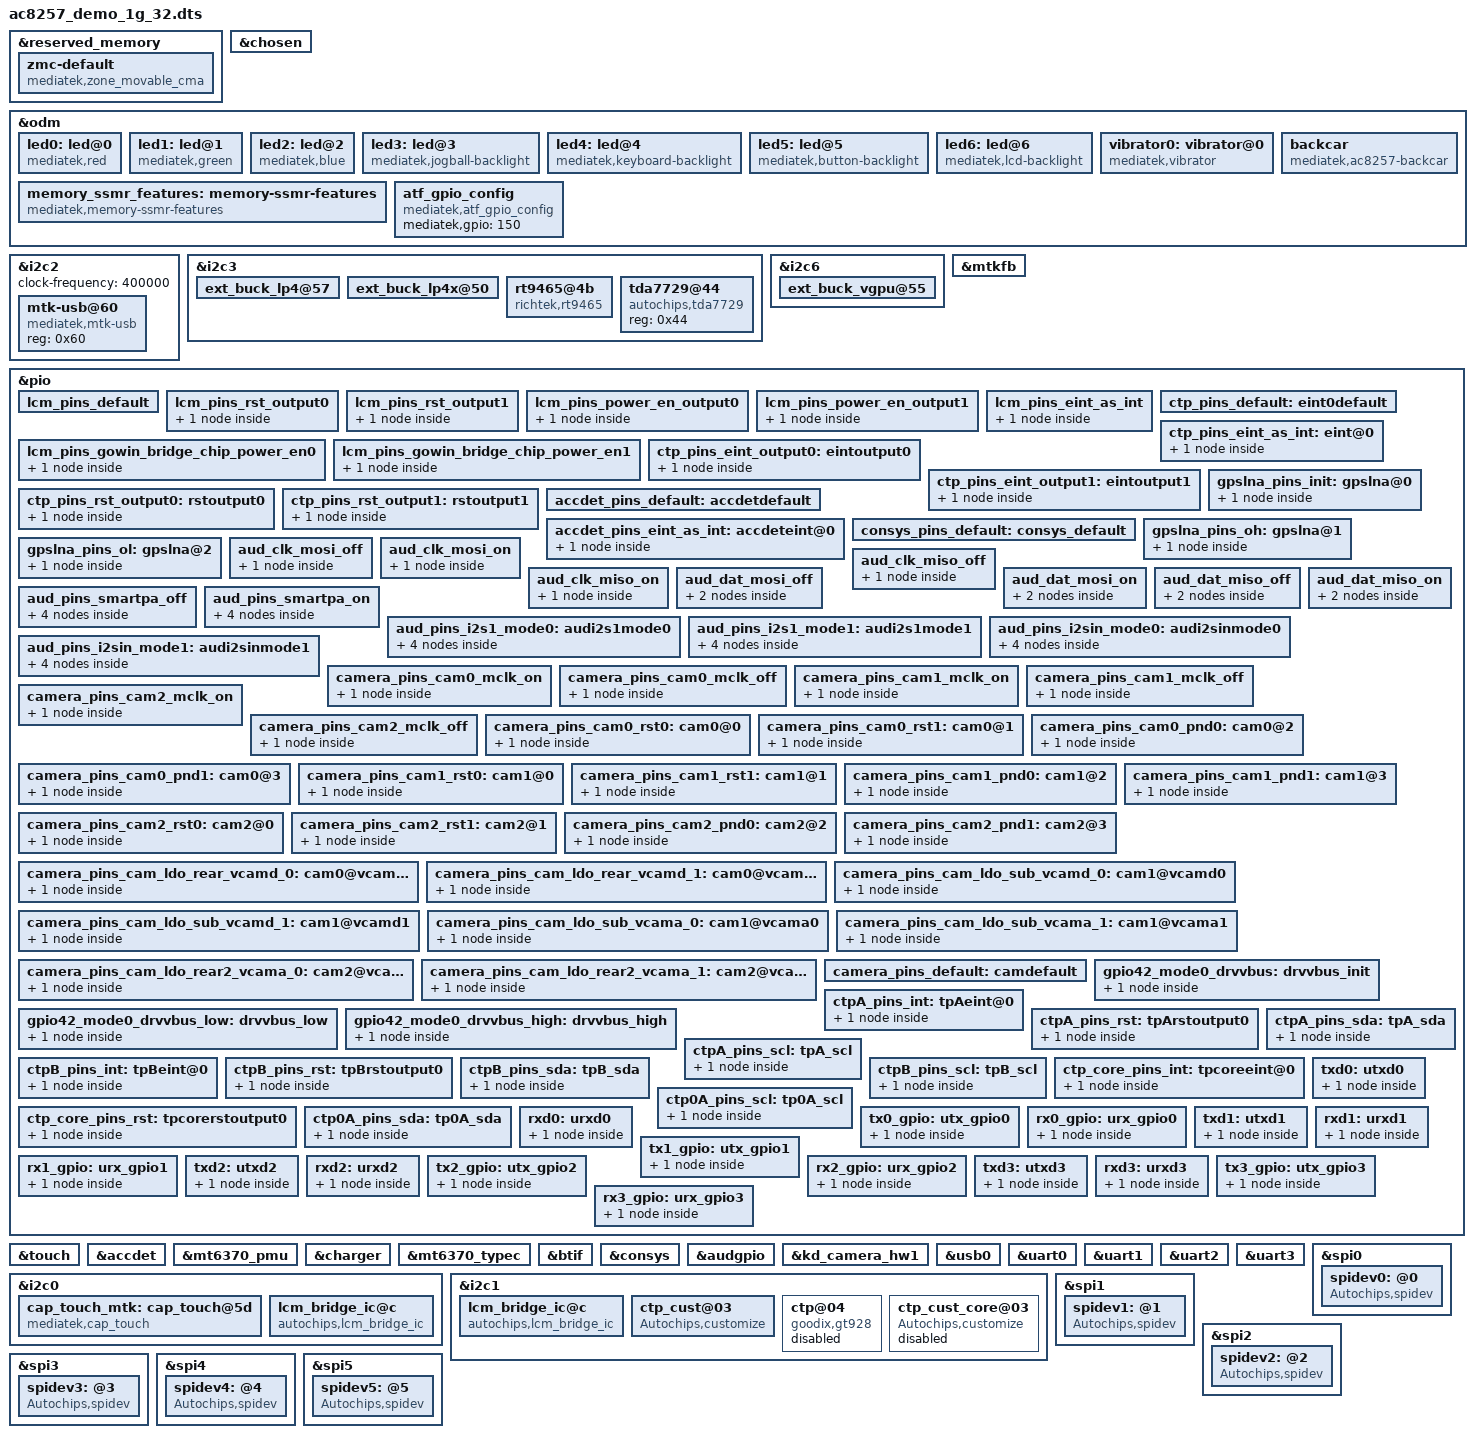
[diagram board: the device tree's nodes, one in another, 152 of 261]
#include <dt-bindings/interrupt-controller/arm-gic.h>
#include <dt-bindings/interrupt-controller/irq.h>
#include <dt-bindings/pinctrl/ac8257-pinfunc.h>
#include <dt-bindings/mmc/ac8257-msdc.h>
#include <dt-bindings/clock/ac8257-clk.h>

/dts-v1/;
/plugin/;

&reserved_memory {
	#address-cells = <2>;
	#size-cells = <2>;
	ranges;

	zmc-default {
		compatible = "mediatek,zone_movable_cma";
		size = <0 0xffc00000>;
		alignment = <0 0x10000000>;
		alloc-ranges = <0 0xc0000000 1 0x00000000>;
	};
};

/* chosen */
&chosen {

	/* fpga may has no lk, we need to specify display info here */
	/* fb buffer is reserved using this dts by memory node above */
	atag,videolfb-fb_base_h = <0x0>;
	atag,videolfb-fb_base_l = <0x5e605000>;
	atag,videolfb-islcmfound = <1>;
	/* because no lk, so lcm is not inited */
	atag,videolfb-islcm_inited = <0>;
	atag,videolfb-fps= <6000>;
	atag,videolfb-vramSize= <0x017bb000>;
	atag,videolfb-lcmname= "nt35521_hd_dsi_vdo_truly_rt5081_drv";
};

&odm {
	led0:led@0 {
		compatible = "mediatek,red";
		led_mode = <0>;
		data = <1>;
		pwm_config = <0 0 0 0 0>;
	};
	led1:led@1 {
		compatible = "mediatek,green";
		led_mode = <0>;
		data = <1>;
		pwm_config = <0 0 0 0 0>;
	};
	led2:led@2 {
		compatible = "mediatek,blue";
		led_mode = <0>;
		data = <1>;
		pwm_config = <0 0 0 0 0>;
	};
	led3:led@3 {
		compatible = "mediatek,jogball-backlight";
		led_mode = <0>;
		data = <1>;
		pwm_config = <0 0 0 0 0>;
	};
	led4:led@4 {
		compatible = "mediatek,keyboard-backlight";
		led_mode = <0>;
		data = <1>;
		pwm_config = <0 0 0 0 0>;
	};
	led5:led@5 {
		compatible = "mediatek,button-backlight";
		led_mode = <0>;
		data = <1>;
		pwm_config = <0 0 0 0 0>;
	};
	led6:led@6 {
		compatible = "mediatek,lcd-backlight";
		led_mode = <5>;
		data = <1>;
		pwm_config = <0 0 0 0 0>;
	};
	vibrator0:vibrator@0 {
		compatible = "mediatek,vibrator";
		vib_timer = <25>;
		vib_limit = <9>;
		vib_vol= <9>;
	};
	memory_ssmr_features: memory-ssmr-features {
		compatible = "mediatek,memory-ssmr-features";
		svp-size = <0 0>;
		iris-recognition-size = <0 0>;
		2d_fr-size = <0 0>;
		tui-size = <0 0>;
		wfd-size = <0 0>;
		prot-sharedmem-size = <0 0>;
	};
	backcar:backcar {
		compatible = "mediatek,ac8257-backcar";
		backcar_sdbc_gpio=<&pio 10 0>;
		backcar_hdbc_gpio=<&pio 6 0>;
		backcar_hdavm_gpio=<&pio 7 0>;
		backcar_mcu_notify_gpio=<&pio 55 0>;
		status="okay";
	};
	atf_gpio_config: atf_gpio_config {
		compatible = "mediatek,atf_gpio_config";
		mediatek,gpio = <150>;
	};
};

&i2c2 {
	#address-cells = <1>;
	#size-cells = <0>;
	clock-frequency = <400000>;

	mtk-usb@60 {
		compatible = "mediatek,mtk-usb";
		reg = <0x60>;
		status = "okay";
	};
};

&i2c3 {
	ext_buck_lp4@57 {
		regulator-name ="ext_buck_vdd2";
		regulator-min-microvolt = <300000>;
		regulator-max-microvolt = <1300000>;
		vsel_pin = <0>;
	};

	ext_buck_lp4x@50 {
		regulator-name ="ext_buck_vddq";
		regulator-min-microvolt = <300000>;
		regulator-max-microvolt = <1300000>;
		vsel_pin = <1>;
	};
};

&i2c6 {
	ext_buck_vgpu@55 {
		regulator-name ="ext_buck_vgpu";
		regulator-min-microvolt = <300000>;
		regulator-max-microvolt = <1300000>;
		vsel_pin = <2>;
	};
};

/*LCM start*/
&mtkfb {
	pinctrl-names = "default", "state_rst_output0", "state_rst_output1", "state_power_en_output0", "state_power_en_output1", "state_eint_as_int", "state_gowin_bridge_chip_power_en0", "state_gowin_bridge_chip_power_en1";
	pinctrl-0 = <&lcm_pins_default>;
	pinctrl-1 = <&lcm_pins_rst_output0>;
	pinctrl-2 = <&lcm_pins_rst_output1>;
	pinctrl-3 = <&lcm_pins_power_en_output0>;
	pinctrl-4 = <&lcm_pins_power_en_output1>;
	pinctrl-5 = <&lcm_pins_eint_as_int>;
	pinctrl-6 = <&lcm_pins_gowin_bridge_chip_power_en0>;
	pinctrl-7 = <&lcm_pins_gowin_bridge_chip_power_en1>;
	interrupt-parent = <&pio>;
	interrupts = <3 IRQ_TYPE_LEVEL_HIGH 3 0>;
	status = "okay";
};
&pio {
	lcm_pins_default: lcm_pins_default {
	};
	lcm_pins_rst_output0: lcm_pins_rst_output0 {
		pins_cmd_dat {
			pinmux = <PINMUX_GPIO45__FUNC_GPIO45>;
			slew-rate = <1>;
			output-low;
		};
	};
	lcm_pins_rst_output1: lcm_pins_rst_output1 {
		pins_cmd_dat {
			pinmux = <PINMUX_GPIO45__FUNC_GPIO45>;
			slew-rate = <1>;
			output-high;
		};
	};
	lcm_pins_power_en_output0: lcm_pins_power_en_output0 {
		pins_cmd_dat {
			pinmux = <PINMUX_GPIO159__FUNC_GPIO159>;
			slew-rate = <1>;
			output-low;
		};
	};
	lcm_pins_power_en_output1: lcm_pins_power_en_output1 {
		pins_cmd_dat {
			pinmux = <PINMUX_GPIO159__FUNC_GPIO159>;
			slew-rate = <1>;
			output-high;
		};
	};
	lcm_pins_eint_as_int: lcm_pins_eint_as_int {
		pins_cmd_dat {
			pinmux = <PINMUX_GPIO3__FUNC_GPIO3>;
			slew-rate = <0>;
			bias-disable;
		};
	};
	lcm_pins_gowin_bridge_chip_power_en0: lcm_pins_gowin_bridge_chip_power_en0 {
		pins_cmd_dat {
			pinmux = <PINMUX_GPIO44__FUNC_GPIO44>;
			output-low;
		};
	};
	lcm_pins_gowin_bridge_chip_power_en1: lcm_pins_gowin_bridge_chip_power_en1 {
		pins_cmd_dat {
			pinmux = <PINMUX_GPIO44__FUNC_GPIO44>;
			slew-rate = <1>;
			output-high;
		};
	};
};
/*LCM end*/

/* TOUCH start */
&touch {
	tpd-resolution = <720 1280>;
	use-tpd-button = <0>;
	tpd-key-num = <3>;
	tpd-key-local= <139 172 158 0>;
	tpd-key-dim-local = <90 883 100 40 230
				 883 100 40 370 883 100 40 0 0 0 0>;
	tpd-max-touch-num = <5>;
	tpd-filter-enable = <1>;
	tpd-filter-pixel-density = <106>;
	tpd-filter-custom-prameters = <0 0 0 0 0 0 0 0 0 0 0 0>;
	tpd-filter-custom-speed = <0 0 0>;
	pinctrl-names = "default", "state_eint_as_int", "state_eint_output0",
		"state_eint_output1", "state_rst_output0", "state_rst_output1";
	pinctrl-0 = <&ctp_pins_default>;
	pinctrl-1 = <&ctp_pins_eint_as_int>;
	pinctrl-2 = <&ctp_pins_eint_output0>;
	pinctrl-3 = <&ctp_pins_eint_output1>;
	pinctrl-4 = <&ctp_pins_rst_output0>;
	pinctrl-5 = <&ctp_pins_rst_output1>;

	interrupt-parent = <&pio>;
	interrupts = <0 IRQ_TYPE_EDGE_FALLING 0 0>;

	status = "okay";
};

&pio {
	ctp_pins_default: eint0default {
	};
	ctp_pins_eint_as_int: eint@0 {
		pins_cmd_dat {
			pinmux = <PINMUX_GPIO0__FUNC_GPIO0>;
			slew-rate = <0>;
			bias-disable;
		};
	};
	ctp_pins_eint_output0: eintoutput0 {
		pins_cmd_dat {
			pinmux = <PINMUX_GPIO0__FUNC_GPIO0>;
			slew-rate = <1>;
			output-low;
		};
	};
	ctp_pins_eint_output1: eintoutput1 {
		pins_cmd_dat {
			pinmux = <PINMUX_GPIO0__FUNC_GPIO0>;
			slew-rate = <1>;
			output-high;
		};
	};
	ctp_pins_rst_output0: rstoutput0 {
		pins_cmd_dat {
			pinmux = <PINMUX_GPIO174__FUNC_GPIO174>;
			slew-rate = <1>;
			output-low;
		};
	};
	ctp_pins_rst_output1: rstoutput1 {
		pins_cmd_dat {
			pinmux = <PINMUX_GPIO174__FUNC_GPIO174>;
			slew-rate = <1>;
			output-high;
		};
	};
};
/* TOUCH end */
&accdet {
	accdet-mic-vol = <6>;
	headset-mode-setting = <0x500 0x500 1 0x1f0 0x800 0x800 0x20 0x44>;
	accdet-plugout-debounce = <1>;
	accdet-mic-mode = <1>;
	headset-eint-level-pol = <8>;
	headset-three-key-threshold = <0 80 220 400>;
	headset-three-key-threshold-CDD = <0 121 192 600>;
	headset-four-key-threshold = <0 58 121 192 400>;
	pinctrl-names = "default", "state_eint_as_int";
	pinctrl-0 = <&accdet_pins_default>;
	pinctrl-1 = <&accdet_pins_eint_as_int>;

	status = "okay";
};
&pio {
	accdet_pins_default: accdetdefault {
	};
	accdet_pins_eint_as_int: accdeteint@0 {
		pins_cmd_dat {
			pinmux = <PINMUX_GPIO9__FUNC_GPIO9>;
			slew-rate = <0>;
			bias-disable;
		};
	};
};

&mt6370_pmu {
	mt6370,intr_gpio_num = <11>; /* direct defined GPIO num */
	mt6370,intr_gpio = <&pio 11 0x0>;
};

&charger {
	algorithm_name = "DualSwitchCharging";
	chg1_ta_ac_charger_current = <2000000>;
	chg2_ta_ac_charger_current = <2000000>;
};

&i2c3 {
	rt9465@4b {
		compatible = "richtek,rt9465";
		reg = <0x4b>;
		status = "okay";
		rt,en_gpio_num = <176>;
		rt,en_gpio = <&pio 176 0x0>;
		rt,intr_gpio_num = <23>; /* direct defined GPIO num */
		rt,intr_gpio = <&pio 23 0x0>;
		interrupt-names = "wdtmri";
		charger_name = "secondary_chg";
		ichg = <1500000>; /* uA */
		mivr = <4500000>; /* uV */
		cv = <4550000>; /* uV */
		ieoc = <700000>; /* uA */
		safety_timer = <12>; /* hour */
		en_st; /* safety timer */
		/* en_te; */
		en_wdt;
	};

	tda7729@44 {
		compatible = "autochips,tda7729";
		reg = <0x44>;
	};
};

&mt6370_typec {
	mt6370pd,intr_gpio_num = <41>; /* direct defined GPIO num */
	mt6370pd,intr_gpio = <&pio 41 0x0>;
};

&btif {
	reg =
		/*btif base*/
		<0 0x1100c000 0 0x1000>,
		/*btif tx dma base*/
		<0 0x11000A80 0 0x80>,
		/*btif rx dma base*/
		<0 0x11000B00 0 0x80>;

	interrupts =
		/*btif irq, IRQS_Sync ID, btif_irq_b*/
		<GIC_SPI 56 IRQ_TYPE_LEVEL_LOW>,
		/*btif tx dma irq*/
		<GIC_SPI 33 IRQ_TYPE_LEVEL_LOW>,
		/*btif rx dma irq*/
		<GIC_SPI 34 IRQ_TYPE_LEVEL_LOW>;
};

/* CONSYS GPIO standardization */
&pio {
	consys_pins_default: consys_default {
	};
	gpslna_pins_init: gpslna@0 {
		pins_cmd_dat {
			pinmux = <PINMUX_GPIO91__FUNC_GPIO91>;
			slew-rate = <0>;
			bias-disable;
			output-low;
		};
	};
	gpslna_pins_oh: gpslna@1 {
		pins_cmd_dat {
			pinmux = <PINMUX_GPIO91__FUNC_GPIO91>;
			slew-rate = <1>;
			output-high;
		};
	};
	gpslna_pins_ol: gpslna@2 {
		pins_cmd_dat {
			pinmux = <PINMUX_GPIO91__FUNC_GPIO91>;
			slew-rate = <1>;
			output-low;
		};
	};
};
&consys {
	pinctrl-names = "default", "gps_lna_state_init",
		"gps_lna_state_oh", "gps_lna_state_ol";
	pinctrl-0 = <&consys_pins_default>;
	pinctrl-1 = <&gpslna_pins_init>;
	pinctrl-2 = <&gpslna_pins_oh>;
	pinctrl-3 = <&gpslna_pins_ol>;
	status = "okay";
};
/* CONSYS end */

/* AUDIO GPIO standardization */
&audgpio {
	pinctrl-names = "aud_clk_mosi_off",
			"aud_clk_mosi_on",
			"aud_clk_miso_off",
			"aud_clk_miso_on",
			"aud_dat_mosi_off",
			"aud_dat_mosi_on",
			"aud_dat_miso_off",
			"aud_dat_miso_on",
			"aud_smartpa_off",
			"aud_smartpa_on",
			"audi2s1-mode0",
			"audi2s1-mode1",
			"audi2sin-mode0",
			"audi2sin-mode1";
	pinctrl-0 = <&aud_clk_mosi_off>;
	pinctrl-1 = <&aud_clk_mosi_on>;
	pinctrl-2 = <&aud_clk_miso_off>;
	pinctrl-3 = <&aud_clk_miso_on>;
	pinctrl-4 = <&aud_dat_mosi_off>;
	pinctrl-5 = <&aud_dat_mosi_on>;
	pinctrl-6 = <&aud_dat_miso_off>;
	pinctrl-7 = <&aud_dat_miso_on>;
	pinctrl-8 = <&aud_pins_smartpa_off>;
	pinctrl-9 = <&aud_pins_smartpa_on>;
	pinctrl-10 = <&aud_pins_i2s1_mode0>;
	pinctrl-11 = <&aud_pins_i2s1_mode1>;
	pinctrl-12 = <&aud_pins_i2sin_mode0>;
	pinctrl-13 = <&aud_pins_i2sin_mode1>;
	status = "okay";
};

&pio {
	aud_clk_mosi_off: aud_clk_mosi_off {
		pins_cmd0_dat {
			pinmux = <PINMUX_GPIO136__FUNC_GPIO136>;
		};
	};

	aud_clk_mosi_on: aud_clk_mosi_on {
		pins_cmd0_dat {
			pinmux = <PINMUX_GPIO136__FUNC_AUD_CLK_MOSI>;
		};
	};

	aud_clk_miso_off: aud_clk_miso_off {
		pins_cmd0_dat {
			pinmux = <PINMUX_GPIO140__FUNC_GPIO140>;
		};
	};

	aud_clk_miso_on: aud_clk_miso_on {
		pins_cmd0_dat {
			pinmux = <PINMUX_GPIO140__FUNC_AUD_CLK_MISO>;
		};
	};

	aud_dat_mosi_off: aud_dat_mosi_off {
		pins_cmd1_dat {
			pinmux = <PINMUX_GPIO138__FUNC_GPIO138>;
			input-enable;
			slew-rate = <0>;
			bias-disable;
		};
		pins_cmd2_dat {
			pinmux = <PINMUX_GPIO139__FUNC_GPIO139>;
			input-enable;
			slew-rate = <0>;
			bias-disable;
		};
	};

	aud_dat_mosi_on: aud_dat_mosi_on {
		pins_cmd1_dat {
			pinmux = <PINMUX_GPIO138__FUNC_AUD_DAT_MOSI0>;
		};
		pins_cmd2_dat {
			pinmux = <PINMUX_GPIO139__FUNC_AUD_DAT_MOSI1>;
		};
	};

	aud_dat_miso_off: aud_dat_miso_off {
		pins_cmd1_dat {
			pinmux = <PINMUX_GPIO142__FUNC_GPIO142>;
			input-enable;
			slew-rate = <0>;
			bias-disable;
		};
		pins_cmd2_dat {
			pinmux = <PINMUX_GPIO143__FUNC_GPIO143>;
			input-enable;
			slew-rate = <0>;
			bias-disable;
		};
	};

	aud_dat_miso_on: aud_dat_miso_on {
		pins_cmd1_dat {
			pinmux = <PINMUX_GPIO142__FUNC_AUD_DAT_MISO0>;
		};
		pins_cmd2_dat {
			pinmux = <PINMUX_GPIO143__FUNC_AUD_DAT_MISO1>;
		};
	};

	aud_pins_smartpa_off: aud_pins_smartpa_off {
		pins_cmd0_dat {
			pinmux = <PINMUX_GPIO17__FUNC_GPIO17>;
		};
		pins_cmd1_dat {
			pinmux = <PINMUX_GPIO18__FUNC_GPIO18>;
		};
		pins_cmd2_dat {
			pinmux = <PINMUX_GPIO19__FUNC_GPIO19>;
		};
		pins_cmd3_dat {
			pinmux = <PINMUX_GPIO20__FUNC_GPIO20>;
		};
	};

	aud_pins_smartpa_on: aud_pins_smartpa_on {
		pins_cmd0_dat {
			pinmux = <PINMUX_GPIO17__FUNC_I2S0_DI>;
		};
		pins_cmd1_dat {
			pinmux = <PINMUX_GPIO18__FUNC_I2S3_BCK>;
		};
		pins_cmd2_dat {
			pinmux = <PINMUX_GPIO19__FUNC_I2S3_LRCK>;
		};
		pins_cmd3_dat {
			pinmux = <PINMUX_GPIO20__FUNC_I2S3_DO>;
		};
	};
	aud_pins_i2s1_mode0: audi2s1mode0 {
		pins_cmd0_dat {
			pinmux = <PINMUX_GPIO25__FUNC_GPIO25>;
		};
		pins_cmd1_dat {
			pinmux = <PINMUX_GPIO26__FUNC_GPIO26>;
		};
		pins_cmd2_dat {
			pinmux = <PINMUX_GPIO27__FUNC_GPIO27>;
		};
		pins_cmd3_dat {
			pinmux = <PINMUX_GPIO28__FUNC_GPIO28>;
		};
	};

	aud_pins_i2s1_mode1: audi2s1mode1 {
		pins_cmd0_dat {
			pinmux = <PINMUX_GPIO25__FUNC_I2S1_MCK>;
		};
		pins_cmd1_dat {
			pinmux = <PINMUX_GPIO26__FUNC_I2S1_BCK>;
		};
		pins_cmd2_dat {
			pinmux = <PINMUX_GPIO27__FUNC_I2S1_LRCK>;
		};
		pins_cmd3_dat {
			pinmux = <PINMUX_GPIO28__FUNC_I2S1_DO>;
		};
	};

	aud_pins_i2sin_mode0: audi2sinmode0 {
		pins_cmd0_dat {
			pinmux = <PINMUX_GPIO21__FUNC_GPIO21>;
		};
		pins_cmd1_dat {
			pinmux = <PINMUX_GPIO22__FUNC_GPIO22>;
		};
		pins_cmd2_dat {
			pinmux = <PINMUX_GPIO23__FUNC_GPIO23>;
		};
		pins_cmd3_dat {
			pinmux = <PINMUX_GPIO24__FUNC_GPIO24>;
		};
	};

	aud_pins_i2sin_mode1: audi2sinmode1 {
		pins_cmd0_dat {
			pinmux = <PINMUX_GPIO21__FUNC_I2S2_MCK>;
		};
		pins_cmd1_dat {
			pinmux = <PINMUX_GPIO22__FUNC_I2S2_BCK>;
		};
		pins_cmd2_dat {
			pinmux = <PINMUX_GPIO23__FUNC_I2S2_LRCK>;
		};
		pins_cmd3_dat {
			pinmux = <PINMUX_GPIO24__FUNC_I2S2_DI>;
		};
	};

};
/* AUDIO end */

&pio {
	camera_pins_cam0_mclk_on: camera_pins_cam0_mclk_on {
		pins_cmd_dat {
			pinmux = <PINMUX_GPIO100__FUNC_CMMCLK1>;
		};
	};
	camera_pins_cam0_mclk_off: camera_pins_cam0_mclk_off {
		pins_cmd_dat {
			pinmux = <PINMUX_GPIO100__FUNC_GPIO100>;
		};
	};
	camera_pins_cam1_mclk_on: camera_pins_cam1_mclk_on {
		pins_cmd_dat {
			pinmux = <PINMUX_GPIO100__FUNC_CMMCLK1>;
		};
	};
	camera_pins_cam1_mclk_off: camera_pins_cam1_mclk_off {
		pins_cmd_dat {
			pinmux = <PINMUX_GPIO100__FUNC_GPIO100>;
		};
	};
	camera_pins_cam2_mclk_on: camera_pins_cam2_mclk_on {
		pins_cmd_dat {
			pinmux = <PINMUX_GPIO99__FUNC_CMMCLK0>;
		};
	};
	camera_pins_cam2_mclk_off: camera_pins_cam2_mclk_off {
		pins_cmd_dat {
			pinmux = <PINMUX_GPIO99__FUNC_GPIO99>;
		};
	};
	camera_pins_cam0_rst0: cam0@0 {
		pins_cmd_dat {
			pinmux = <PINMUX_GPIO102__FUNC_GPIO102>;
			slew-rate = <1>;
			output-low;
		};
	};
	camera_pins_cam0_rst1: cam0@1 {
		pins_cmd_dat {
			pinmux = <PINMUX_GPIO102__FUNC_GPIO102>;
			slew-rate = <1>;
			output-high;
		};
	};
	camera_pins_cam0_pnd0: cam0@2 {
		pins_cmd_dat {
			pinmux = <PINMUX_GPIO98__FUNC_GPIO98>;
			slew-rate = <1>;
			output-low;
		};
	};
	camera_pins_cam0_pnd1: cam0@3 {
		pins_cmd_dat {
			pinmux = <PINMUX_GPIO98__FUNC_GPIO98>;
			slew-rate = <1>;
			output-high;
		};
	};
	camera_pins_cam1_rst0: cam1@0 {
		pins_cmd_dat {
			pinmux = <PINMUX_GPIO101__FUNC_GPIO101>;
			slew-rate = <1>;
			output-low;
		};
	};
	camera_pins_cam1_rst1: cam1@1 {
		pins_cmd_dat {
			pinmux = <PINMUX_GPIO101__FUNC_GPIO101>;
			slew-rate = <1>;
			output-high;
		};
	};
	camera_pins_cam1_pnd0: cam1@2 {
		pins_cmd_dat {
			pinmux = <PINMUX_GPIO97__FUNC_GPIO97>;
			slew-rate = <1>;
			output-low;
		};
	};
	camera_pins_cam1_pnd1: cam1@3 {
		pins_cmd_dat {
			pinmux = <PINMUX_GPIO97__FUNC_GPIO97>;
			slew-rate = <1>;
			output-high;
		};
	};
	camera_pins_cam2_rst0: cam2@0 {
		pins_cmd_dat {
			pinmux = <PINMUX_GPIO166__FUNC_GPIO166>;
			slew-rate = <1>;
			output-low;
		};
	};
	camera_pins_cam2_rst1: cam2@1 {
		pins_cmd_dat {
			pinmux = <PINMUX_GPIO166__FUNC_GPIO166>;
			slew-rate = <1>;
			output-high;
		};
	};
	camera_pins_cam2_pnd0: cam2@2 {
		pins_cmd_dat {
			pinmux = <PINMUX_GPIO107__FUNC_GPIO107>;
			slew-rate = <1>;
			output-low;
		};
	};
	camera_pins_cam2_pnd1: cam2@3 {
		pins_cmd_dat {
			pinmux = <PINMUX_GPIO107__FUNC_GPIO107>;
			slew-rate = <1>;
			output-high;
		};
	};
	camera_pins_cam_ldo_rear_vcamd_0: cam0@vcamd0 {
		pins_cmd_dat {
			pinmux = <PINMUX_GPIO88__FUNC_GPIO88>;
			slew-rate = <1>;
			output-low;
		};
	};
	camera_pins_cam_ldo_rear_vcamd_1: cam0@vcamd1 {
		pins_cmd_dat {
			pinmux = <PINMUX_GPIO88__FUNC_GPIO88>;
			slew-rate = <1>;
			output-high;
		};
	};
	camera_pins_cam_ldo_sub_vcamd_0: cam1@vcamd0 {
		pins_cmd_dat {
			pinmux = <PINMUX_GPIO170__FUNC_GPIO170>;
			slew-rate = <1>;
			output-low;
		};
	};
	camera_pins_cam_ldo_sub_vcamd_1: cam1@vcamd1 {
		pins_cmd_dat {
			pinmux = <PINMUX_GPIO170__FUNC_GPIO170>;
			slew-rate = <1>;
			output-high;
		};
	};
	camera_pins_cam_ldo_sub_vcama_0: cam1@vcama0 {
		pins_cmd_dat {
			pinmux = <PINMUX_GPIO169__FUNC_GPIO169>;
			slew-rate = <1>;
			output-low;
		};
	};
	camera_pins_cam_ldo_sub_vcama_1: cam1@vcama1 {
		pins_cmd_dat {
			pinmux = <PINMUX_GPIO169__FUNC_GPIO169>;
			slew-rate = <1>;
			output-high;
		};
	};
	camera_pins_cam_ldo_rear2_vcama_0: cam2@vcama0 {
		pins_cmd_dat {
			pinmux = <PINMUX_GPIO169__FUNC_GPIO169>;
			slew-rate = <1>;
			output-low;
		};
	};
	camera_pins_cam_ldo_rear2_vcama_1: cam2@vcama1 {
		pins_cmd_dat {
			pinmux = <PINMUX_GPIO169__FUNC_GPIO169>;
			slew-rate = <1>;
			output-high;
		};
	};
	camera_pins_default: camdefault {
	};

};

&kd_camera_hw1 {
	pinctrl-names = "default",
			"cam0_rst0",
			"cam0_rst1",
			"cam0_pnd0",
			"cam0_pnd1",
			"cam1_rst0",
			"cam1_rst1",
			"cam1_pnd0",
			"cam1_pnd1",
			"cam2_rst0",
			"cam2_rst1",
			"cam2_pnd0",
			"cam2_pnd1",
			"cam0_vcamd_on",
			"cam0_vcamd_off",
			"cam1_vcamd_on",
			"cam1_vcamd_off",
			"cam1_vcama_on",
			"cam1_vcama_off",
			"cam2_vcama_on",
			"cam2_vcama_off",
			"cam0_mclk_on",
			"cam0_mclk_off",
			"cam1_mclk_on",
			"cam1_mclk_off",
			"cam2_mclk_on",
			"cam2_mclk_off";

	pinctrl-0 = <&camera_pins_default>;
	pinctrl-1 = <&camera_pins_cam0_rst0>;
	pinctrl-2 = <&camera_pins_cam0_rst1>;
	pinctrl-3 = <&camera_pins_cam0_pnd0>;
	pinctrl-4 = <&camera_pins_cam0_pnd1>;
	pinctrl-5 = <&camera_pins_cam1_rst0>;
	pinctrl-6 = <&camera_pins_cam1_rst1>;
	pinctrl-7 = <&camera_pins_cam1_pnd0>;
	pinctrl-8 = <&camera_pins_cam1_pnd1>;
	pinctrl-9 = <&camera_pins_cam2_rst0>;
	pinctrl-10 = <&camera_pins_cam2_rst1>;
	pinctrl-11 = <&camera_pins_cam2_pnd0>;
	pinctrl-12 = <&camera_pins_cam2_pnd1>;
	pinctrl-13 = <&camera_pins_cam_ldo_rear_vcamd_1>;
	pinctrl-14 = <&camera_pins_cam_ldo_rear_vcamd_0>;
	pinctrl-15 = <&camera_pins_cam_ldo_sub_vcamd_1>;
	pinctrl-16 = <&camera_pins_cam_ldo_sub_vcamd_0>;
	pinctrl-17 = <&camera_pins_cam_ldo_sub_vcama_1>;
	pinctrl-18 = <&camera_pins_cam_ldo_sub_vcama_0>;
	pinctrl-19 = <&camera_pins_cam_ldo_rear2_vcama_1>;
	pinctrl-20 = <&camera_pins_cam_ldo_rear2_vcama_0>;
	pinctrl-21 = <&camera_pins_cam0_mclk_on>;
	pinctrl-22 = <&camera_pins_cam0_mclk_off>;
	pinctrl-23 = <&camera_pins_cam1_mclk_on>;
	pinctrl-24 = <&camera_pins_cam1_mclk_off>;
	pinctrl-25 = <&camera_pins_cam2_mclk_on>;
	pinctrl-26 = <&camera_pins_cam2_mclk_off>;
	status = "okay";

};

&pio {
/* USB GPIO start */
	gpio42_mode0_drvvbus: drvvbus_init {
		pins_cmd_dat {
			pinmux = <PINMUX_GPIO42__FUNC_GPIO42>;
			slew-rate = <1>;
			output-low;
		};
	};

	gpio42_mode0_drvvbus_low: drvvbus_low {
		pins_cmd_dat {
			pinmux = <PINMUX_GPIO42__FUNC_GPIO42>;
			slew-rate = <1>;
			output-low;
		};
	};

	gpio42_mode0_drvvbus_high: drvvbus_high {
		pins_cmd_dat {
			pinmux = <PINMUX_GPIO42__FUNC_GPIO42>;
			slew-rate = <1>;
			output-high;
		};
	};
};


&usb0 {
	pinctrl-names = "drvvbus_init", "drvvbus_low", "drvvbus_high";
	pinctrl-0 = <&gpio42_mode0_drvvbus>;
	pinctrl-1 = <&gpio42_mode0_drvvbus_low>;
	pinctrl-2 = <&gpio42_mode0_drvvbus_high>;
	status = "okay";
};

#include <ac8257_demo_1g_32/cust.dtsi>


&pio {
	ctpA_pins_int: tpAeint@0 {
				   pins_cmd_dat {
					   pinmux = <PINMUX_GPIO0__FUNC_GPIO0>;
					   slew-rate = <0>;
					   bias-pull-up;
				   };
			   };

	ctpA_pins_rst: tpArstoutput0 {
					   pins_cmd_dat {
						   pinmux = <PINMUX_GPIO174__FUNC_GPIO174>;
						   slew-rate = <1>;
					   };
				   };
	ctpA_pins_sda: tpA_sda {
					   pins_cmd_dat {
						   pinmux = <PINMUX_GPIO81__FUNC_SDA1>;
						   slew-rate = <1>;
						   drive-strength = <7>;
					   };
				   };
	ctpA_pins_scl: tpA_scl {
					   pins_cmd_dat {
						   pinmux = <PINMUX_GPIO84__FUNC_SCL1>;
						   slew-rate = <1>;
						   drive-strength = <7>;
					   };
				   };

	ctpB_pins_int: tpBeint@0 {
					   pins_cmd_dat {
						   pinmux = <PINMUX_GPIO12__FUNC_GPIO12>;
						   slew-rate = <0>;
						   bias-pull-up;
					   };
				   };

	ctpB_pins_rst: tpBrstoutput0 {
					   pins_cmd_dat {
						   pinmux = <PINMUX_GPIO178__FUNC_GPIO178>;
						   slew-rate = <1>;
					   };
				   };
	ctpB_pins_sda: tpB_sda {
					   pins_cmd_dat {
						   pinmux = <PINMUX_GPIO81__FUNC_SDA1>;
						   slew-rate = <1>;
						   drive-strength = <7>;
					   };
				   };
	ctpB_pins_scl: tpB_scl {
					   pins_cmd_dat {
						   pinmux = <PINMUX_GPIO84__FUNC_SCL1>;
						   slew-rate = <1>;
						   drive-strength = <7>;
					   };
				   };

	ctp_core_pins_int: tpcoreeint@0 {
					   pins_cmd_dat {
						   pinmux = <PINMUX_GPIO5__FUNC_GPIO5>;
						   slew-rate = <0>;
						   bias-pull-up;
					   };
				   };

	ctp_core_pins_rst: tpcorerstoutput0 {
					   pins_cmd_dat {
						   pinmux = <PINMUX_GPIO4__FUNC_GPIO4>;
						   slew-rate = <1>;
					   };
				   };
};


&pio {
	ctp0A_pins_sda: tp0A_sda {
				   pins_cmd_dat {
					   pinmux = <PINMUX_GPIO82__FUNC_SDA0>;
					   slew-rate = <1>;
					   drive-strength = <7>;
				   };
	};
	ctp0A_pins_scl: tp0A_scl {
			   pins_cmd_dat {
				   pinmux = <PINMUX_GPIO83__FUNC_SCL0>;
				   slew-rate = <1>;
				   drive-strength = <7>;
			   };
	};
};


&pio {
	txd0: utxd0 {
			pins_cmd_dat {
			pinmux = <PINMUX_GPIO96__FUNC_UTXD0>;
			};
	};
	rxd0: urxd0{
			pins_cmd_dat {
			pinmux = <PINMUX_GPIO95__FUNC_URXD0>;
			};
	};
	tx0_gpio: utx_gpio0 {
			pins_cmd_dat {
			pinmux = <PINMUX_GPIO96__FUNC_GPIO96>;
			};
	};
	rx0_gpio: urx_gpio0{
			pins_cmd_dat {
			pinmux = <PINMUX_GPIO95__FUNC_GPIO95>;
			};
	};
	txd1: utxd1 {
			pins_cmd_dat {
			pinmux = <PINMUX_GPIO107__FUNC_UTXD1>;
			};
	};
	rxd1: urxd1{
			pins_cmd_dat {
			pinmux = <PINMUX_GPIO109__FUNC_URXD1>;
			};
	};
	tx1_gpio: utx_gpio1 {
			pins_cmd_dat {
			pinmux = <PINMUX_GPIO107__FUNC_GPIO107>;
			};
	};
	rx1_gpio: urx_gpio1{
			pins_cmd_dat {
			pinmux = <PINMUX_GPIO109__FUNC_GPIO109>;
			};
	};
	txd2: utxd2 {
			pins_cmd_dat {
			pinmux = <PINMUX_GPIO180__FUNC_UTXD2>;
			};
	};
	rxd2: urxd2{
			pins_cmd_dat {
			pinmux = <PINMUX_GPIO179__FUNC_URXD2>;
			};
	};
	tx2_gpio: utx_gpio2 {
			pins_cmd_dat {
			pinmux = <PINMUX_GPIO180__FUNC_GPIO180>;
			};
	};
	rx2_gpio: urx_gpio2 {
			pins_cmd_dat {
			pinmux = <PINMUX_GPIO179__FUNC_GPIO179>;
			};
	};
	txd3: utxd3 {
			pins_cmd_dat {
			pinmux = <PINMUX_GPIO182__FUNC_UTXD3>;
			};
	};
	rxd3: urxd3{
			pins_cmd_dat {
			pinmux = <PINMUX_GPIO181__FUNC_URXD3>;
			};
	};
	tx3_gpio: utx_gpio3 {
			pins_cmd_dat {
			pinmux = <PINMUX_GPIO182__FUNC_GPIO182>;
			};
	};
	rx3_gpio: urx_gpio3 {
			pins_cmd_dat {
			pinmux = <PINMUX_GPIO181__FUNC_GPIO181>;
			};
	};
};

&uart0 {
		pinctrl-names = "utxd", "urxd", "tx_gpio","rx_gpio";
		pinctrl-0 = <&txd0>;
		pinctrl-1 = <&rxd0>;
		pinctrl-2 = <&tx0_gpio>;
		pinctrl-3 = <&rx0_gpio>;
};
&uart1 {
		pinctrl-names = "utxd", "urxd", "tx_gpio","rx_gpio";
		pinctrl-0 = <&txd1>;
		pinctrl-1 = <&rxd1>;
		pinctrl-2 = <&tx1_gpio>;
		pinctrl-3 = <&rx1_gpio>;

};
&uart2 {
		pinctrl-names = "utxd", "urxd", "tx_gpio","rx_gpio";
		pinctrl-0 = <&txd2>;
		pinctrl-1 = <&rxd2>;
		pinctrl-2 = <&tx2_gpio>;
		pinctrl-3 = <&rx2_gpio>;
};
&uart3 {
		pinctrl-names = "utxd", "urxd", "tx_gpio","rx_gpio";
		pinctrl-0 = <&txd3>;
		pinctrl-1 = <&rxd3>;
		pinctrl-2 = <&tx3_gpio>;
		pinctrl-3 = <&rx3_gpio>;
};

&i2c0 {
	cap_touch_mtk:cap_touch@5d {
		  compatible = "mediatek,cap_touch";
		  reg = <0x5d>;

		  ti-link = <0x0>;
		  ti-serializer = <0x1a>;  /* <0x1a>; */
		  ti-deserializer = <0x2C>;  /* <0x2C>; */

		  status = "okay";
	};

	lcm_bridge_ic@c {
		compatible = "autochips,lcm_bridge_ic";
		reg = <0x0c>;
		lcm_id = <0>;
		status = "okay";
        };
};

&i2c1 {
	#address-cells = <1>;
	#size-cells = <0>;
	clock-frequency = <100000>;
	multiplexing = <1>; /* multiplexing by arm2 */

	lcm_bridge_ic@c {
		compatible = "autochips,lcm_bridge_ic";
		reg = <0x0c>;
		lcm_id = <1>;
		status = "okay";
	};

	/* 720P demo board */
	ctp_cust@03 {
		compatible = "Autochips,customize";
		pinctrl-names = "sda", "scl", "int", "rst";
		pinctrl-0 = <&ctpB_pins_sda>;
		pinctrl-1 = <&ctpB_pins_scl>;
		pinctrl-2 = <&ctpB_pins_int>;
		pinctrl-3 = <&ctpB_pins_rst>;

		reg = <0x1A>;
		touchscreen-abs-x-max = <1920>;
		touchscreen-abs-y-max = <720>;

		serializer-addr = <0x0E>;
		deserializer-addr = <0x2C>;

		touchpad-addr = <0x1A>;

		touchscreen-extern = <0>;

		reset-gpios = <&pio 178 0>;
		irq-gpios = <&pio 12 0>;

		irq_mode = <0x1>;

		interrupt-parent = <&pio>;
		interrupts = <12 IRQ_TYPE_EDGE_FALLING 12 0>;

		status = "okay";
	};

	/* 720P Main  */
	ctp@04 {
		compatible = "goodix,gt928";
		pinctrl-names = "sda", "scl", "int", "rst";
		pinctrl-0 = <&ctpA_pins_sda>;
		pinctrl-1 = <&ctpA_pins_scl>;
		pinctrl-2 = <&ctpB_pins_int>;
		pinctrl-3 = <&ctpB_pins_rst>;

		reg = <0x2>;
		reset-gpios = <&pio 178 0>;
		irq-gpios = <&pio 12 0>;

		irq_mode = <0x1>;
		slave_addr = <0x14>;

		interrupt-parent = <&pio>;
		interrupts = <12 IRQ_TYPE_EDGE_FALLING 12 0>;

		/* abs-x-max abs-y-max swapped-x-y inverted-x inverted-y */
		tps-info = <1024 600 0 0 0
			720 1920 1 0 0
			0 0 0 0 0 >;
		touchscreen-supported = <2>;

		touchscreen-extern = <0>;

		ti-link = <0x4>;
		ti-serializer = <0x1a>;  /* <0x1a>; */
		ti-deserializer = <0x2c>;  /* <0x2C>; */
		status = "disabled";
	};

	/* 720P Main Core board */
	ctp_cust_core@03 {
		compatible = "Autochips,customize";
		pinctrl-names = "sda", "scl", "int", "rst";
		pinctrl-0 = <&ctp0A_pins_sda>;
		pinctrl-1 = <&ctp0A_pins_scl>;
		pinctrl-2 = <&ctp_core_pins_int>;
		pinctrl-3 = <&ctp_core_pins_rst>;

		reg = <0x1A>;
		touchscreen-abs-x-max = <1920>;
		touchscreen-abs-y-max = <720>;

		serializer-addr = <0x0E>;
		deserializer-addr = <0x2D>;

		touchpad-addr = <0x1A>;

		touchscreen-extern = <0>;

		reset-gpios = <&pio 4 0>;
		irq-gpios = <&pio 5 0>;

		irq_mode = <0x1>;

		interrupt-parent = <&pio>;
		interrupts = <5 IRQ_TYPE_EDGE_FALLING 5 0>;

		status = "disabled";
	};
};

&spi0 {
	spidev0:@0 {
	compatible = "Autochips,spidev";
	reg = <0x0>;
	spi-max-frequency = <52000000>;
	status = "okay";
	};
};

&spi1 {
	spidev1:@1 {
	compatible = "Autochips,spidev";
	reg = <0x0>;
	spi-max-frequency = <52000000>;
	status = "okay";
	};
};

&spi2 {
	spidev2:@2 {
	compatible = "Autochips,spidev";
	reg = <0x0>;
	spi-max-frequency = <52000000>;
	status = "okay";
	};
};

&spi3 {
	spidev3:@3 {
	compatible = "Autochips,spidev";
	reg = <0x0>;
	spi-max-frequency = <52000000>;
	status = "okay";
	};
};

&spi4 {
	spidev4:@4 {
	compatible = "Autochips,spidev";
	reg = <0x0>;
	spi-max-frequency = <52000000>;
	status = "okay";
	};
};

&spi5 {
	spidev5:@5 {
	compatible = "Autochips,spidev";
	reg = <0x0>;
	spi-max-frequency = <52000000>;
	status = "okay";
	};
};

/*End of this file, DO NOT ADD ANYTHING HERE*/
